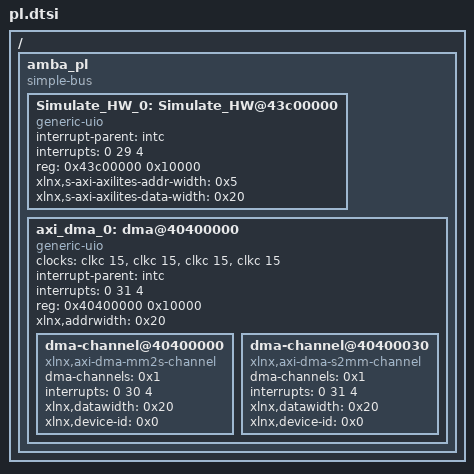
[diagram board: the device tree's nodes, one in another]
/*
 * CAUTION: This file is automatically generated by Xilinx.
 * Version:  
 * Today is: Sat Oct 20 15:17:12 2018
*/


/ {

	amba_pl:amba_pl {
    		#address-cells = <1>;
    		#size-cells = <1>;
    		compatible = "simple-bus";
    		ranges ;
    
		Simulate_HW_0: Simulate_HW@43c00000 {
        		compatible = "generic-uio";
        		interrupt-parent = <&intc>;
        		interrupts = <0 29 4>;
        		reg = <0x43c00000 0x10000>;
        		xlnx,s-axi-axilites-addr-width = <0x5>;
        		xlnx,s-axi-axilites-data-width = <0x20>;
    		};
    
		axi_dma_0: dma@40400000 {
        		#dma-cells = <1>;
        		clock-names = "s_axi_lite_aclk", "m_axi_sg_aclk", "m_axi_mm2s_aclk", "m_axi_s2mm_aclk";
        		clocks = <&clkc 15>, <&clkc 15>, <&clkc 15>, <&clkc 15>;
        		compatible = "generic-uio";
        		interrupt-parent = <&intc>;
        		interrupts = <0 31 4>;
        		reg = <0x40400000 0x10000>;
        		xlnx,addrwidth = <0x20>;
        		dma-channel@40400000 {
            			compatible = "xlnx,axi-dma-mm2s-channel";
            			dma-channels = <0x1>;
            			interrupts = <0 30 4>;
            			xlnx,datawidth = <0x20>;
            			xlnx,device-id = <0x0>;
       		 	};
        		dma-channel@40400030 {
            			compatible = "xlnx,axi-dma-s2mm-channel";
            			dma-channels = <0x1>;
            			interrupts = <0 31 4>;
            			xlnx,datawidth = <0x20>;
            			xlnx,device-id = <0x0>;
        		};
    		};
	};

};



